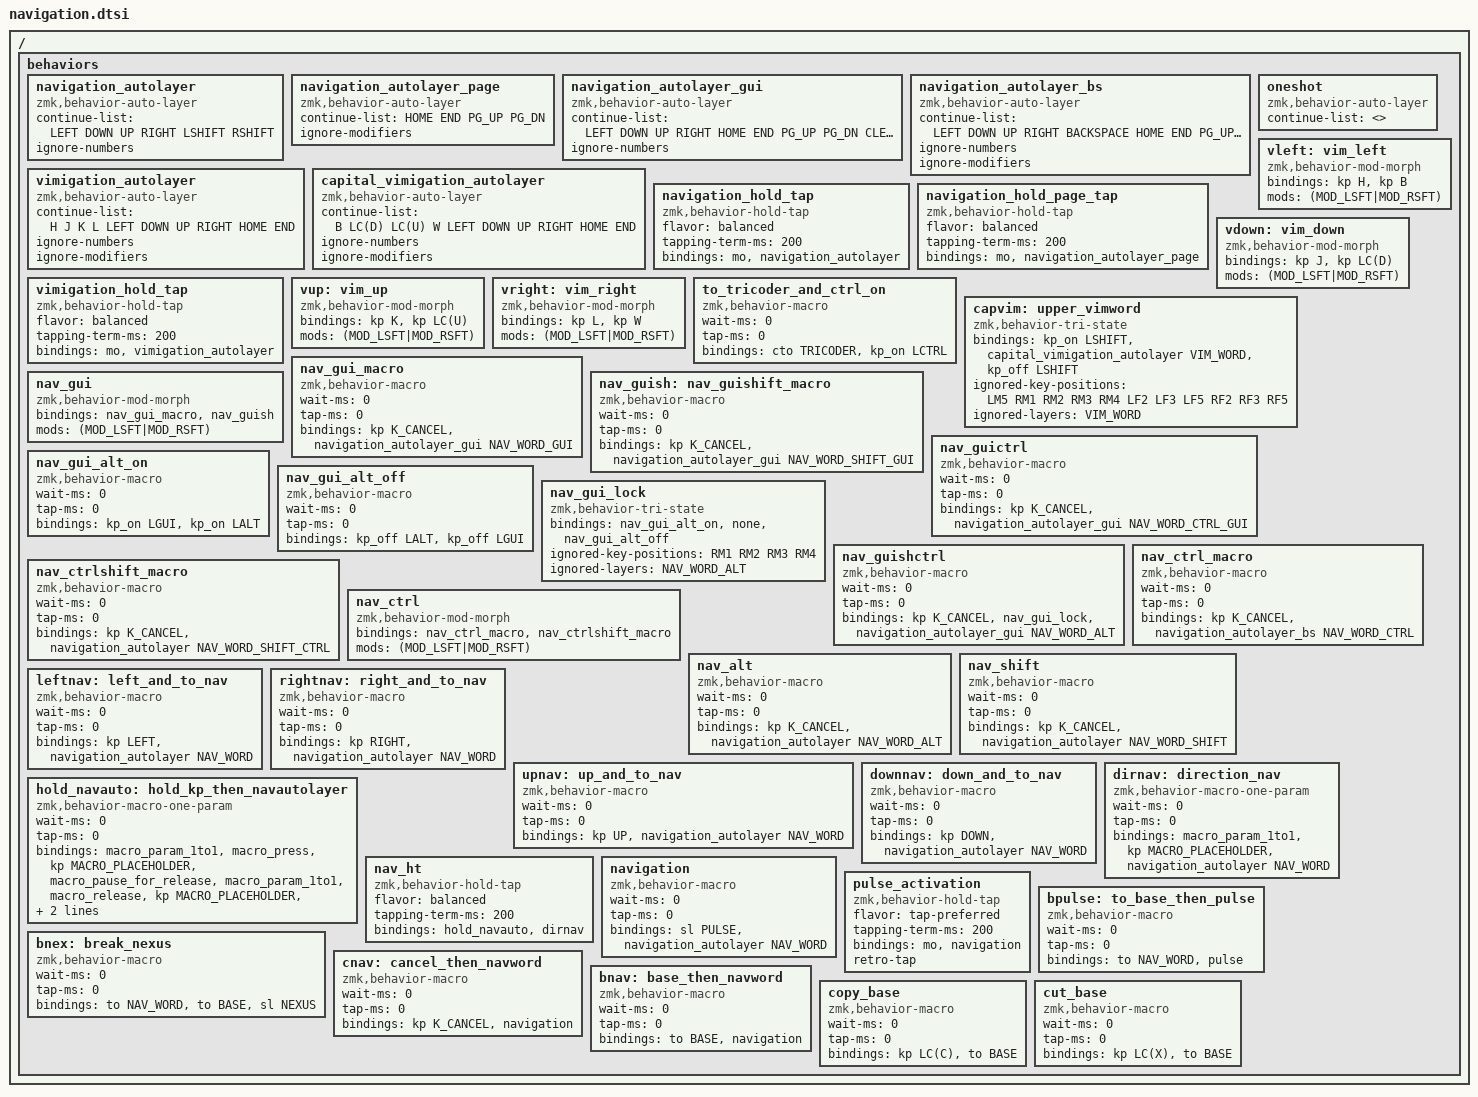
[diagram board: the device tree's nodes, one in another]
/ {
	behaviors {

		navigation_autolayer: navigation_autolayer {
			compatible = "zmk,behavior-auto-layer";
			#binding-cells = <1>;
			continue-list = <LEFT DOWN UP RIGHT /* villt alls ekki CLEAR_AGAIN hér því notar það í amps */
                      LSHIFT RSHIFT
                       /* LCTRL RCTRL */
                       /*  LALT RALT */
      >; /* sleppa mods því nota pulse til að komast í þá og hef modded nav anyway (plús örvarnar á base) */
      /* ókei nánar tiltekið um mods: vilt að gui og alt canceli af því comboin overlappa við örvarnar */
      /* ah nei já vilt líklega líka að ctrl canceli út af stöffi eins og ctrl t,  */
      /* on held það sleppi að leyfa shift, þó ég sé kominn með shift nav */
			ignore-numbers;
			/* ignore-modifiers; */
		};

		navigation_autolayer_page: navigation_autolayer_page {
			compatible = "zmk,behavior-auto-layer";
			#binding-cells = <1>;
			continue-list = <HOME END PG_UP PG_DN>;
			ignore-modifiers;
		};

    /* þetta var gert til að laga bug sem lét amps virka illa með nav autolayernum */
    /* skipti út fyrir tristate */
		/* camps: cancelling_amps { */
		/* 	compatible = "zmk,behavior-macro"; */
		/* 	#binding-cells = <0>; */
		/* 	wait-ms = <0>; */
		/* 	tap-ms = <0>; */
		/* 	bindings = <&kp AMPS>, <&kp CLEAR_AGAIN>; */
		/* }; */

		navigation_autolayer_gui: navigation_autolayer_gui {
			compatible = "zmk,behavior-auto-layer";
			#binding-cells = <1>;
			continue-list = <LEFT DOWN UP RIGHT HOME END PG_UP PG_DN CLEAR_AGAIN
                       LSHIFT RSHIFT LCTRL RCTRL LALT RALT>;
			ignore-numbers;
			/* ignore-modifiers; */
		};

		navigation_autolayer_bs: navigation_autolayer_bs {
			compatible = "zmk,behavior-auto-layer";
			#binding-cells = <1>;
			continue-list = <LEFT DOWN UP RIGHT BACKSPACE HOME END PG_UP PG_DN CLEAR_AGAIN>;
			ignore-numbers;
			ignore-modifiers;
		};

		vimigation_autolayer: vimigation_autolayer {
			compatible = "zmk,behavior-auto-layer";
			#binding-cells = <1>;
			continue-list = <H J K L LEFT DOWN UP RIGHT HOME END>;
			ignore-numbers;
			ignore-modifiers;
		};

		capital_vimigation_autolayer: capital_vimigation_autolayer {
			compatible = "zmk,behavior-auto-layer";
			#binding-cells = <1>;
			continue-list = <B LC(D) LC(U) W LEFT DOWN UP RIGHT HOME END>;
			ignore-numbers;
			ignore-modifiers;
		};

		oneshot: oneshot {
			compatible = "zmk,behavior-auto-layer";
			#binding-cells = <1>;
			continue-list = <>;
		};

		/* navigation_with_overlay: navigation_with_overlay { */
		/* 	compatible = "zmk,behavior-macro"; */
		/* 	#binding-cells = <0>; */
		/* 	bindings = < */
		/* 	&navigation_autolayer NAV_WORD */
		/* 	&navigation_autolayer KCAN_OVER */
		/* 	>; */
		/* }; */
		
		/* navigation_mod_morph: navigation_mod_morph { */
		/*     compatible = "zmk,behavior-mod-morph"; */
		/*     #binding-cells = <0>; */
		/*     bindings = <&navigation_with_overlay>, <&to NAVIGATION>; */
		/*     mods = <(MOD_LSFT|MOD_RSFT)>; */
		/* }; */

		navigation_hold_tap: navigation_hold_tap {
		  compatible = "zmk,behavior-hold-tap";
		  #binding-cells = <2>;
		  flavor = "balanced";
		  tapping-term-ms = <200>;
		  bindings = <&mo>, <&navigation_autolayer>;
		};

		navigation_hold_page_tap: navigation_hold_page_tap {
		  compatible = "zmk,behavior-hold-tap";
		  #binding-cells = <2>;
		  flavor = "balanced";
		  tapping-term-ms = <200>;
		  bindings = <&mo>, <&navigation_autolayer_page>;
		};

		vimigation_hold_tap: vimigation_hold_tap {
		  compatible = "zmk,behavior-hold-tap";
		  #binding-cells = <2>;
		  flavor = "balanced";
		  tapping-term-ms = <200>;
		  bindings = <&mo>, <&vimigation_autolayer>;
		};


    #define navigation_base navigation_hold_tap NAV_WORD NAV_WORD
    #define nav_mirrored navigation_autolayer NAV_WORD_MIRRORED
    #define vim vimigation_hold_tap VIM_WORD VIM_WORD
    #define pag navigation_hold_page_tap PAGE_WORD PAGE_WORD


		vleft: vim_left {
			compatible = "zmk,behavior-mod-morph";
			#binding-cells = <0>;
			bindings = <&kp H>, <&kp B>;
			mods = <(MOD_LSFT|MOD_RSFT)>;
		};

		vdown: vim_down {
			compatible = "zmk,behavior-mod-morph";
			#binding-cells = <0>;
			bindings = <&kp J>, <&kp LC(D)>;
			mods = <(MOD_LSFT|MOD_RSFT)>;
		};

		vup: vim_up {
			compatible = "zmk,behavior-mod-morph";
			#binding-cells = <0>;
			bindings = <&kp K>, <&kp LC(U)>;
			mods = <(MOD_LSFT|MOD_RSFT)>;
		};

		vright: vim_right {
			compatible = "zmk,behavior-mod-morph";
			#binding-cells = <0>;
			bindings = <&kp L>, <&kp W>;
			mods = <(MOD_LSFT|MOD_RSFT)>;
		};

		to_tricoder_and_ctrl_on: to_tricoder_and_ctrl_on {
			compatible = "zmk,behavior-macro";
			#binding-cells = <0>;
			wait-ms = <0>;
			tap-ms = <0>;
			bindings = <&cto TRICODER>, <&kp_on LCTRL>;
		};

		capvim: upper_vimword {
				compatible = "zmk,behavior-tri-state";
				#binding-cells = <0>;
				bindings = <&kp_on LSHIFT>, <&capital_vimigation_autolayer VIM_WORD>, <&kp_off LSHIFT>;
				ignored-key-positions = <LM5 RM1 RM2 RM3 RM4 LF2 LF3 LF5 RF2 RF3 RF5>;
				ignored-layers = <VIM_WORD>;
		};

    /* #define nav_gui navigation_autolayer_gui NAV_WORD_GUI */
    /* #define nav_ctrl navigation_autolayer_bs NAV_WORD_CTRL */
    /* #define nav_alt navigation_autolayer NAV_WORD_ALT */
    /* #define nav_shift navigation_autolayer NAV_WORD_SHIFT */
		nav_gui_macro: nav_gui_macro {
			compatible = "zmk,behavior-macro";
			#binding-cells = <0>;
			wait-ms = <0>;
			tap-ms = <0>;
			bindings = <&kp K_CANCEL>, <&navigation_autolayer_gui NAV_WORD_GUI>;
		};

		nav_guish: nav_guishift_macro {
			compatible = "zmk,behavior-macro";
			#binding-cells = <0>;
			wait-ms = <0>;
			tap-ms = <0>;
			bindings = <&kp K_CANCEL>, <&navigation_autolayer_gui NAV_WORD_SHIFT_GUI>;
		};

		nav_gui: nav_gui {
			compatible = "zmk,behavior-mod-morph";
			#binding-cells = <0>;
			bindings = <&nav_gui_macro>, <&nav_guish>;
			mods = <(MOD_LSFT|MOD_RSFT)>;
		};

		nav_guictrl: nav_guictrl {
			compatible = "zmk,behavior-macro";
			#binding-cells = <0>;
			wait-ms = <0>;
			tap-ms = <0>;
			bindings = <&kp K_CANCEL>, <&navigation_autolayer_gui NAV_WORD_CTRL_GUI >;
		};

		nav_gui_alt_on: nav_gui_alt_on {
			compatible = "zmk,behavior-macro";
			#binding-cells = <0>;
			wait-ms = <0>;
			tap-ms = <0>;
			bindings = <&kp_on LGUI>, <&kp_on LALT>;
		};

		nav_gui_alt_off: nav_gui_alt_off {
			compatible = "zmk,behavior-macro";
			#binding-cells = <0>;
			wait-ms = <0>;
			tap-ms = <0>;
			bindings = <&kp_off LALT>, <&kp_off LGUI>;
		};

		nav_gui_lock: nav_gui_lock {
			compatible = "zmk,behavior-tri-state";
			#binding-cells = <0>;
			bindings = <&nav_gui_alt_on>, <&none>, <&nav_gui_alt_off>;
			ignored-key-positions = <RM1 RM2 RM3 RM4>;
			ignored-layers = <NAV_WORD_ALT>;
		};

		nav_guishctrl: nav_guishctrl {
			compatible = "zmk,behavior-macro";
			#binding-cells = <0>;
			wait-ms = <0>;
			tap-ms = <0>;
			bindings = <&kp K_CANCEL>, <&nav_gui_lock>, <&navigation_autolayer_gui NAV_WORD_ALT>;
		};

		nav_ctrl_macro: nav_ctrl_macro {
			compatible = "zmk,behavior-macro";
			#binding-cells = <0>;
			wait-ms = <0>;
			tap-ms = <0>;
			bindings = <&kp K_CANCEL>, <&navigation_autolayer_bs NAV_WORD_CTRL>;
		};

		nav_ctrlshift_macro: nav_ctrlshift_macro {
			compatible = "zmk,behavior-macro";
			#binding-cells = <0>;
			wait-ms = <0>;
			tap-ms = <0>;
			bindings = <&kp K_CANCEL>, <&navigation_autolayer NAV_WORD_SHIFT_CTRL>;
		};

		nav_ctrl: nav_ctrl {
			compatible = "zmk,behavior-mod-morph";
			#binding-cells = <0>;
			bindings = <&nav_ctrl_macro>, <&nav_ctrlshift_macro>;
			mods = <(MOD_LSFT|MOD_RSFT)>;
		};

		nav_alt: nav_alt {
			compatible = "zmk,behavior-macro";
			#binding-cells = <0>;
			wait-ms = <0>;
			tap-ms = <0>;
			bindings = <&kp K_CANCEL>, <&navigation_autolayer NAV_WORD_ALT>;
		};

		nav_shift: nav_shift {
			compatible = "zmk,behavior-macro";
			#binding-cells = <0>;
			wait-ms = <0>;
			tap-ms = <0>;
			bindings = <&kp K_CANCEL>, <&navigation_autolayer NAV_WORD_SHIFT>;
		};

		leftnav: left_and_to_nav {
			compatible = "zmk,behavior-macro";
			#binding-cells = <0>;
			wait-ms = <0>;
			tap-ms = <0>;
			bindings = <&kp LEFT>, <&navigation_autolayer NAV_WORD>;
		};

		rightnav: right_and_to_nav {
			compatible = "zmk,behavior-macro";
			#binding-cells = <0>;
			wait-ms = <0>;
			tap-ms = <0>;
			bindings = <&kp RIGHT>, <&navigation_autolayer NAV_WORD>;
		};

		upnav: up_and_to_nav {
			compatible = "zmk,behavior-macro";
			#binding-cells = <0>;
			wait-ms = <0>;
			tap-ms = <0>;
			bindings = <&kp UP>, <&navigation_autolayer NAV_WORD>;
		};

		downnav: down_and_to_nav {
			compatible = "zmk,behavior-macro";
			#binding-cells = <0>;
			wait-ms = <0>;
			tap-ms = <0>;
			bindings = <&kp DOWN>, <&navigation_autolayer NAV_WORD>;
		};

		dirnav: direction_nav {
        compatible = "zmk,behavior-macro-one-param";
        wait-ms = <0>;
        tap-ms = <0>;
        #binding-cells = <1>;
			  bindings = <&macro_param_1to1>, <&kp MACRO_PLACEHOLDER>, <&navigation_autolayer NAV_WORD>;
		};


    hold_navauto: hold_kp_then_navautolayer {
        compatible = "zmk,behavior-macro-one-param";
        wait-ms = <0>;
        tap-ms = <0>;
        #binding-cells = <1>;
        bindings
            = 
            <&macro_param_1to1>
            , <&macro_press &kp MACRO_PLACEHOLDER>
            , <&macro_pause_for_release>
            , <&macro_param_1to1>
            , <&macro_release &kp MACRO_PLACEHOLDER>
            , <&macro_param_2to1>
            , <&navigation_autolayer NAV_WORD>
            ;
    };

		nav_ht: nav_ht {
		  compatible = "zmk,behavior-hold-tap";
		  #binding-cells = <2>;
		  flavor = "balanced";
		  tapping-term-ms = <200>;
		  bindings = <&hold_navauto>, <&dirnav>;
		};

    #define leftnav nav_ht LEFT LEFT
    #define downnav nav_ht DOWN DOWN
    #define upnav nav_ht UP UP
    #define rightnav nav_ht RIGHT RIGHT

    /* #define leftnav hold_navauto LEFT NAV_WORD */
    /* #define downnav hold_navauto DOWN NAV_WORD */
    /* #define upnav hold_navauto UP NAV_WORD */
    /* #define rightnav hold_navauto RIGHT NAV_WORD */


		navigation: navigation {
			compatible = "zmk,behavior-macro";
			#binding-cells = <0>;
			wait-ms = <0>;
			tap-ms = <0>;
			bindings = <&sl PULSE>, <&navigation_autolayer NAV_WORD>;
		};

		pulse_activation: pulse_activation {
		  compatible = "zmk,behavior-hold-tap";
		  #binding-cells = <2>;
      flavor = "tap-preferred";
		  tapping-term-ms = <200>;
		  bindings = <&mo>, <&navigation>;
      retro-tap;
		};

    #define pulse pulse_activation PULSE 0

		bpulse: to_base_then_pulse {
			compatible = "zmk,behavior-macro";
			#binding-cells = <0>;
			wait-ms = <0>;
			tap-ms = <0>;
			bindings = <&to NAV_WORD>, <&pulse>;
      /* hugmyndin er augljóslega ekki að fara á nav word, þarf bara að brjóta tristate */
		};

		bnex: break_nexus {
			compatible = "zmk,behavior-macro";
			#binding-cells = <0>;
			wait-ms = <0>;
			tap-ms = <0>;
			bindings = <&to NAV_WORD>, <&to BASE>, <&sl NEXUS>;
      /* hugmyndin er augljóslega ekki að fara á nav word, þarf bara að brjóta tristate */
		};

		/* bnexus: base_nexus { */
		/* 	compatible = "zmk,behavior-macro"; */
		/* 	#binding-cells = <0>; */
		/* 	wait-ms = <0>; */
		/* 	tap-ms = <0>; */
		/* 	bindings = <&to BASE>, <&sl NEXUS>; */
		/* }; */

		cnav: cancel_then_navword {
			compatible = "zmk,behavior-macro";
			#binding-cells = <0>;
			wait-ms = <0>;
			tap-ms = <0>;
			bindings = <&kp K_CANCEL>, <&navigation>;
		};

		bnav: base_then_navword {
			compatible = "zmk,behavior-macro";
			#binding-cells = <0>;
			wait-ms = <0>;
			tap-ms = <0>;
			bindings = <&to BASE>, <&navigation>;
		};


		copy_base: copy_base {
			compatible = "zmk,behavior-macro";
			#binding-cells = <0>;
			wait-ms = <0>;
			tap-ms = <0>;
			bindings = <&kp LC(C)>, <&to BASE>;
		};


		cut_base: cut_base {
			compatible = "zmk,behavior-macro";
			#binding-cells = <0>;
			wait-ms = <0>;
			tap-ms = <0>;
			bindings = <&kp LC(X)>, <&to BASE>;
		};

		/* navigation: navigation { */
		/* 	compatible = "zmk,behavior-mod-morph"; */
		/* 	#binding-cells = <0>; */
		/* 	bindings = <&navigation_hold_tap NAV_WORD NAV_WORD>, <&vimigation_hold_tap VIM_WORD VIM_WORD>; */
		/* 	mods = <(MOD_LSFT|MOD_RSFT)>; */
		/* 	keep-mods = <(MOD_LSFT)>; */
		/* }; */


    /* hmm eftirfarandi væri kúl til að spara layers en fæ ekki til að virka */
		/* shift_on_and_nav: shift_on_and_nav { */
		/* 	compatible = "zmk,behavior-macro"; */
		/* 	#binding-cells = <0>; */
		/* 	wait-ms = <0>; */
		/* 	tap-ms = <0>; */
		/* 	bindings = <&kp_on LSHIFT>, <&to NAV_WORD>; */
		/* }; */
		/* shift_off_and_cancel: shift_off_and_cancel { */
		/* 	compatible = "zmk,behavior-macro"; */
		/* 	#binding-cells = <0>; */
		/* 	wait-ms = <0>; */
		/* 	tap-ms = <0>; */
		/* 	bindings = <&kp_off LSHIFT>, <&to BASE>; */
		/* }; */
		/* nav_shift: nav_shift { */
		/* 		compatible = "zmk,behavior-tri-state"; */
		/* 		#binding-cells = <0>; */
		/* 		bindings = <&none>, <&shift_on_and_nav>, <&shift_off_and_cancel>; */
		/* 		ignored-key-positions = <RM1 RM2 RM3 RM4 LM1 LM2>; */
		/*       timeout-ms = <6000>; */
		/* }; */

	};
};
